# R7FA6M5BH register map
Vendor: Renesas Electronics Corporation; Series: RA6; File version: 1.20.01
CPU: CM33 r0p4, little endian, MPU, FPU, VTOR, 4 interrupt priority bits, 96 interrupts
Registers are 32-bit, read-write, reset 0x0 unless marked. A register's access mark holds for its fields unless they carry their own. Offsets are from the block's base; [hi:lo] are bit positions; 'fields as' and 'values as' point back to an identical list.

## TZF — TrustZone Filter
Base 0x40000E00
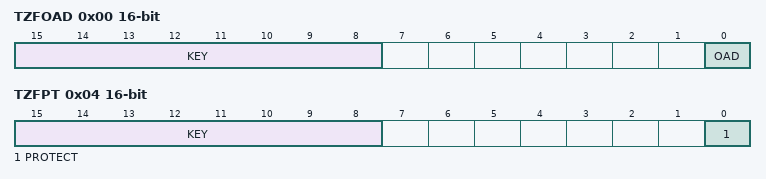
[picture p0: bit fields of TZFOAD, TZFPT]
0x00 TZFOAD 16-bit — TrustZone Filter Operation After Detection Register
  [15:8] KEY wo — KeyCode
  [0] OAD — Operation after detection
    0=Non-maskable interrupt; 1=Reset
0x04 TZFPT 16-bit — TrustZone Filter Protect Register
  [15:8] KEY wo — KeyCode
  [0] PROTECT — Protection of register
    0=All Bus TrustZone Filter register writing is protected. Read is possible.; 1=All Bus TrustZone Filter register writing is possible

## SRAM — SRAM Control
Base 0x40002000
0x00 PARIOAD 8-bit — SRAM Parity Error Operation After Detection Register
  [0] OAD — Operation After Detection
    0=Non-maskable interrupt; 1=Reset
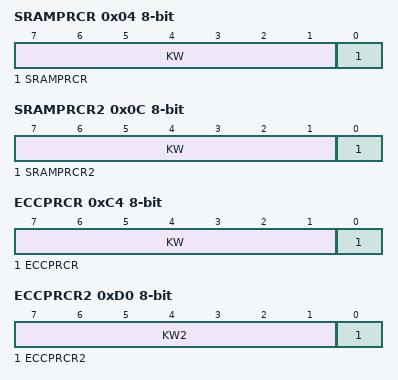
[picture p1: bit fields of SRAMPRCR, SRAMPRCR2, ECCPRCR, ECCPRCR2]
0x04 SRAMPRCR 8-bit — SRAM Protection Register
  [7:1] KW wo — Write Key Code
  [0] SRAMPRCR — Register Write Control
    0=Disable writes to protected registers; 1=Enable writes to protected registers
0x08 SRAMWTSC 8-bit reset 0x1 — SRAM Wait State Control Register
  [0] SRAM0WTEN — SRAM0 wait enable
    0=No wait; 1=Add wait state in read access cycle to SRAM0
0x0C SRAMPRCR2 8-bit — SRAM Protection Register 2
  [7:1] KW wo — Write Key Code
  [0] SRAMPRCR2 — Register Write Control
    0=Disable writes to the protectedregisters; 1=Enable writes to the protected registers
0xC0 ECCMODE 8-bit — ECC Operating Mode Control Register
  [1:0] ECCMOD — ECC Operating Mode Select
    0=Disable ECC function; 1=Setting prohibited; 2=Enable ECC function without error checking; 3=Enable ECC function with error checking
0xC1 ECC2STS 8-bit — ECC 2-Bit Error Status Register
  [0] ECC2ERR — ECC 2-Bit Error Status
    0=No 2-bit ECC error occurred; 1=2-bit ECC error occurred
0xC2 ECC1STSEN 8-bit — ECC 1-Bit Error Information Update Enable Register
  [0] E1STSEN — ECC 1-Bit Error Information Update Enable
    0=Disable updating of 1-bit ECC error information; 1=Enable updating of 1-bit ECC error information
0xC3 ECC1STS 8-bit — ECC 1-Bit Error Status Register
  [0] ECC1ERR — ECC 1-Bit Error Status
    0=No 1-bit ECC error occurred; 1=1-bit ECC error occurred
0xC4 ECCPRCR 8-bit — ECC Protection Register
  [7:1] KW wo — Write Key Code
    120=Enable write to the ECCPRCR bit; other=Others (Disable write to the ECCPRCR bit)
  [0] ECCPRCR — Register Write Control
    0=Disable writes to the protected registers; 1=Enable writes to the protected registers
0xD0 ECCPRCR2 8-bit — ECC Protection Register 2
  [7:1] KW2 wo — Write Key Code
    120=Enable write to the ECCPRCR2 bit; other=Others (Disable write to the ECCPRCR2 bit)
  [0] ECCPRCR2 — Register Write Control
    values as ECCPRCR.ECCPRCR
0xD4 ECCETST 8-bit — ECC Test Control Register
  [0] TSTBYP — ECC Bypass Select
    0=Disable ECC bypass; 1=Enable ECC bypass
0xD8 ECCOAD 8-bit — SRAM ECC Error Operation After Detection Register
  fields as PARIOAD

## DMA — DMAC Module Activation
Base 0x40005200
0x00 DMAST 8-bit — DMA Module Activation Register
  [0] DMST — DMAC Operation Enable
    0=DMAC activation is disabled; 1=DMAC activation is enabled
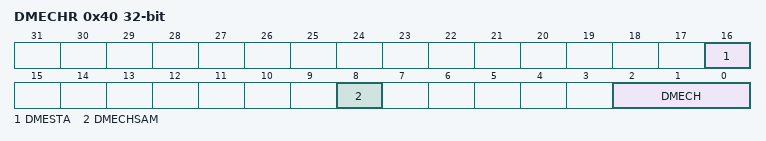
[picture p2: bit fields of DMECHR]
0x40 DMECHR — DMAC Error Channel Register
  [16] DMESTA — DMAC Error Status
    0=No DMA transfer error occurred; 1=DMA transfer error occurred
  [8] DMECHSAM ro — DMAC Error channel Security Attribution Monitor
    0=secure channel; 1=non-secure channel
  [2:0] DMECH ro — DMAC Error channel

## DTC — Data Transfer Controller
Base 0x40005400
0x00 DTCCR 8-bit reset 0x8 — DTC Control Register
  [4] RRS — DTC Transfer Information Read Skip Enable
    0=Transfer information read is not skipped; 1=Transfer information read is skipped when vector numbers match
0x04 DTCVBR — DTC Vector Base Register
0x0C DTCST 8-bit — DTC Module Start Register
  [0] DTCST — DTC Module Start
    0=DTC module stopped; 1=DTC module started
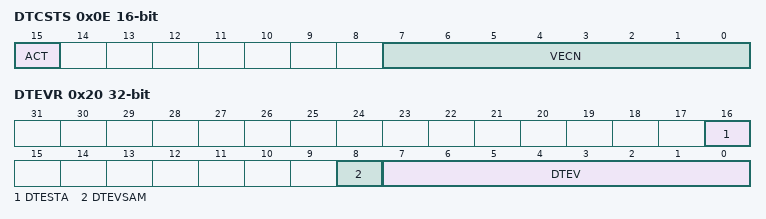
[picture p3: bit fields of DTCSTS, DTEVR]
0x0E DTCSTS 16-bit ro — DTC Status Register
  [15] ACT — DTC Active Flag
    0=DTC transfer operation is not in progress; 1=DTC transfer operation is in progress
  [7:0] VECN — DTC-Activating Vector Number Monitoring
0x10 DTCCR_SEC 8-bit reset 0x8 — DTC Control Register for secure Region
  [4] RRS — DTC Transfer Information Read Skip Enable for Secure
    values as DTCCR.RRS
0x14 DTCVBR_SEC — DTC Vector Base Register for secure Region
0x20 DTEVR — DTC Error Vector Register
  [16] DTESTA — DTC Error Status Flag
    0=No DTC transfer error occurred; 1=DTC transfer error occurred
  [8] DTEVSAM ro — DTC Error Vector Number SA Monitor
    0=Secure vector number; 1=Non-Secure vector number
  [7:0] DTEV ro — DTC Error Vector Number

## Notices in the file
This software is supplied by Renesas Electronics Corporation and is only intended for
use with Renesas products. No other uses are authorized. This software is owned by
Renesas Electronics Corporation and is protected under all applicable laws, including
copyright laws.
THIS SOFTWARE IS PROVIDED "AS IS" AND RENESAS MAKES NO WARRANTIES REGARDING
THIS SOFTWARE, WHETHER EXPRESS, IMPLIED OR STATUTORY, INCLUDING BUT NOT LIMITED TO
WARRANTIES OF MERCHANTABILITY, FITNESS FOR A PARTICULAR PURPOSE AND NON-INFRINGEMENT.
ALL SUCH WARRANTIES ARE EXPRESSLY DISCLAIMED. TO THE MAXIMUM EXTENT PERMITTED NOT
PROHIBITED BY LAW, NEITHER RENESAS ELECTRONICS CORPORATION NOR ANY OF ITS AFFILIATED
COMPANIES SHALL BE LIABLE FOR ANY DIRECT, INDIRECT, SPECIAL, INCIDENTAL OR CONSEQUENTIAL
DAMAGES FOR ANY REASON RELATED TO THIS SOFTWARE, EVEN IF RENESAS OR ITS AFFILIATES HAVE
BEEN ADVISED OF THE POSSIBILITY OF SUCH DAMAGES.
Renesas reserves the right, without notice, to make changes to this software and to
discontinue the availability of this software. By using this software, you agree to
the additional terms and conditions found by accessing the following link:
http://www.renesas.com/disclaimer
